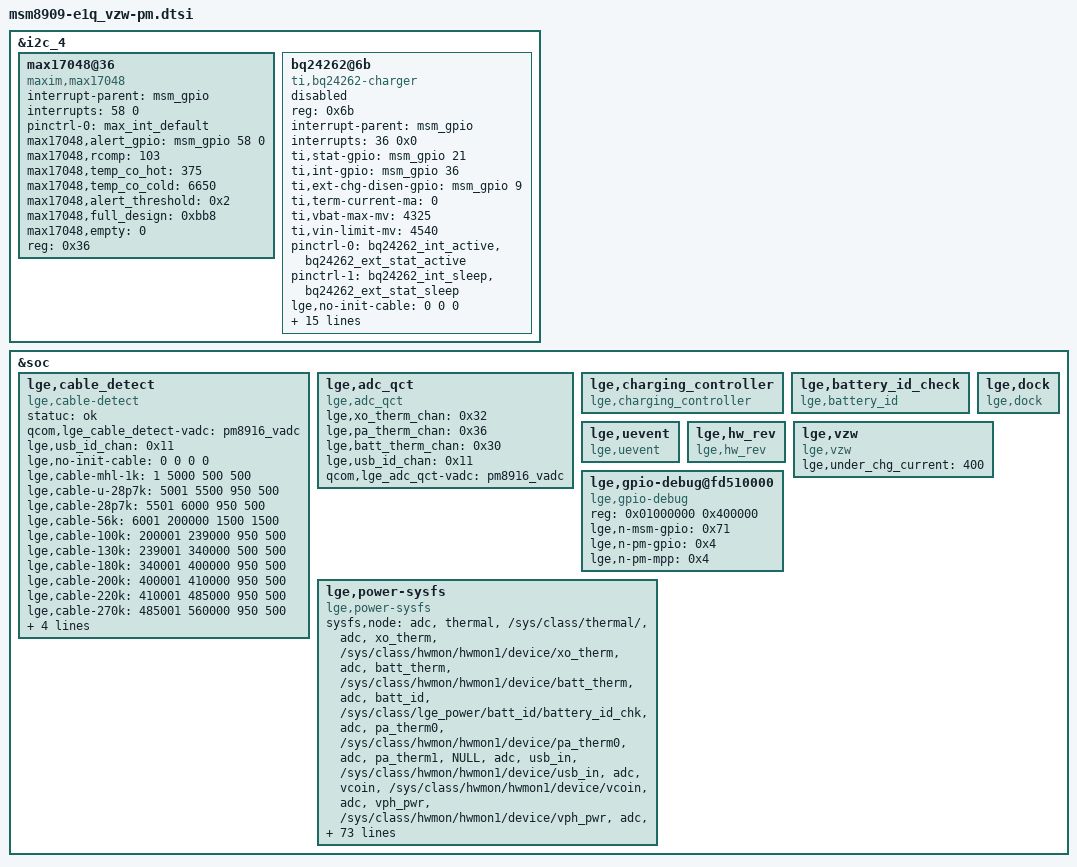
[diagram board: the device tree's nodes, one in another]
/* Copyright (c) 2014, The Linux Foundation. All rights reserved.
 *
 * This program is free software; you can redistribute it and/or modify
 * it under the terms of the GNU General Public License version 2 and
 * only version 2 as published by the Free Software Foundation.
 *
 * This program is distributed in the hope that it will be useful,
 * but WITHOUT ANY WARRANTY; without even the implied warranty of
 * MERCHANTABILITY or FITNESS FOR A PARTICULAR PURPOSE.  See the
 * GNU General Public License for more details.
 */

&i2c_4 {
	/* BLSP1 QUP4 */
	max17048@36 {
		compatible = "maxim,max17048";
		interrupt-parent = <&msm_gpio>;
		interrupts = <58 0>;
		pinctrl-names = "default";
		pinctrl-0 = <&max_int_default>;
		max17048,alert_gpio = <&msm_gpio 58 0>;
		max17048,rcomp = <103>;
		max17048,temp_co_hot = <375>;
		max17048,temp_co_cold = <6650>;
		max17048,alert_threshold = <0x2>;
		max17048,full_design = <0xbb8>;
		max17048,empty = <0>;
		reg = <0x36>;
	};

	bq24262@6b {
		status = "disabled";
		compatible = "ti,bq24262-charger";
		reg = <0x6b>;
		interrupt-parent = <&msm_gpio>;
		interrupts = <36 0x0>;
		ti,stat-gpio = <&msm_gpio 21 0>;
		ti,int-gpio = <&msm_gpio 36 0>;
		ti,ext-chg-disen-gpio = <&msm_gpio 9 0>;
		ti,term-current-ma = <0>;
		ti,vbat-max-mv = <4325>;	/* Step unit 20 mV, battery available voltage(x = 4.375) : x-0.025 ~ x ~ x+0.025 */
		ti,vin-limit-mv = <4540>;
		/* Pins config setting */
		pinctrl-names = "default", "sleep";
		pinctrl-0 = <&bq24262_int_active &bq24262_ext_stat_active>;
		pinctrl-1 = <&bq24262_int_sleep &bq24262_ext_stat_sleep>;

		/* Each model is defferently value */
		lge,no-init-cable = <0 0 0>;
		lge,cable-mhl-1k = <5000 500 500>;
		lge,cable-u-28p7k = <5500 1200 500>;
		lge,cable-28p7k = <6000 1200 500>;
		lge,cable-56k = <200000 1500 1500>;
		lge,cable-100k = <239000 1200 500>;
		lge,cable-130k = <340000 1500 1500>;
		lge,cable-180k = <400000 1200 500>;
		lge,cable-200k = <410000 1200 500>;
		lge,cable-220k = <485000 1200 500>;
		lge,cable-270k = <560000 1200 500>;
		lge,cable-330k = <735000 1200 500>;
		lge,cable-620k = <955000 1200 500>;
		lge,cable-910k = <1140000 1500 1500>;
		lge,cable-none = <1900000 1200  500>;

		qcom,bq24262-vadc = <&pm8909_vadc>;
	};
};

&soc {

	lge,cable_detect {
		statuc = "ok";
		compatible = "lge,cable-detect";
		qcom,lge_cable_detect-vadc = <&pm8916_vadc>;

		lge,usb_id_chan = <0x11>;

		lge,no-init-cable = <0 0 0 0>;
		lge,cable-mhl-1k = <1 5000 500 500>;
		lge,cable-u-28p7k = <5001 5500 950 500>;
		lge,cable-28p7k = <5501 6000 950 500>;
		lge,cable-56k = <6001 200000 1500 1500>;
		lge,cable-100k = <200001 239000 950 500>;
		lge,cable-130k = <239001 340000 500 500>;
		lge,cable-180k = <340001 400000 950 500>;
		lge,cable-200k = <400001 410000 950 500>;
		lge,cable-220k = <410001 485000 950 500>;
		lge,cable-270k = <485001 560000 950 500>;
		lge,cable-330k = <560001 735000 950 500>;
		lge,cable-620k = <735001 955000 950 500>;
		lge,cable-910k = <955001 1140000 1500 1500>;
		lge,cable-none = <1140001 1900000 950 500>;
	};

	lge,adc_qct {
		compatible = "lge,adc_qct";
		lge,xo_therm_chan = <0x32>;
		lge,pa_therm_chan = <0x36>;
		lge,batt_therm_chan = <0x30>;
		lge,usb_id_chan = <0x11>;
		qcom,lge_adc_qct-vadc = <&pm8916_vadc>;
	};

	lge,charging_controller {
		compatible = "lge,charging_controller";
	};

	lge,battery_id_check {
		compatible = "lge,battery_id";
	};

	lge,dock {
		compatible = "lge,dock";
	};

	lge,uevent {
		compatible = "lge,uevent";
	};

	lge,hw_rev {
		compatible = "lge,hw_rev";
	};

	lge,vzw {
		compatible = "lge,vzw";
		lge,under_chg_current = <400>;
	};

	lge,gpio-debug@fd510000 {
		compatible = "lge,gpio-debug";
		reg = <0x01000000 0x400000>;
		reg-names = "tlmm-base";
		lge,n-msm-gpio = <0x71>;
		lge,n-pm-gpio = <0x4>;
		lge,n-pm-mpp = <0x4>;
	};
};

&soc {
	lge,power-sysfs {
		compatible = "lge,power-sysfs";

		sysfs,node =
			/* group , user_node,  kernel node */
			/* ADC/MPP */
			"adc", "thermal", "/sys/class/thermal/",
			"adc", "xo_therm", "/sys/class/hwmon/hwmon1/device/xo_therm",
			"adc", "batt_therm", "/sys/class/hwmon/hwmon1/device/batt_therm",
			"adc", "batt_id", "/sys/class/lge_power/batt_id/battery_id_chk",
			"adc", "pa_therm0", "/sys/class/hwmon/hwmon1/device/pa_therm0",
			"adc", "pa_therm1", "NULL",
			"adc", "usb_in", "/sys/class/hwmon/hwmon1/device/usb_in",
			"adc", "vcoin", "/sys/class/hwmon/hwmon1/device/vcoin",
			"adc", "vph_pwr", "/sys/class/hwmon/hwmon1/device/vph_pwr",
			"adc", "usb_id", "/sys/class/hwmon/hwmon1/device/usb_id",
			/* Battery */
			"battery", "capacity", "/sys/class/power_supply/battery/capacity",
			"battery", "health", "/sys/class/power_supply/battery/health",
			"battery", "present", "/sys/class/power_supply/battery/present",
			"battery", "pseudo_batt", "/sys/class/power_supply/battery/pseudo_batt",
			"battery", "status", "/sys/class/power_supply/battery/status",
			"battery", "temp", "/sys/class/power_supply/battery/temp",
			"battery", "valid_batt_id", "/sys/class/lge_power/batt_id/valid_batt_id",
			"battery", "voltage_now", "/sys/class/power_supply/battery/voltage_now",
			"battery", "check_batt_id_for_aat", "/sys/class/lge_power/batt_id/batt_id_for_aat",
			"battery", "vzw_chg", "/sys/class/lge_power/vzw/vzw_chg",
			/* Charger */
			"charger", "ac_online", "NULL",
			"charger", "usb_online", "/sys/class/power_supply/usb/online",
			"charger", "present", "/sys/class/power_supply/usb/present",
			"charger", "wlc_online", "NULL",
			"charger", "type", "/sys/class/power_supply/usb/type",
			"charger", "time_out", "/sys/class/power_supply/battery/safety_timer",
			"charger", "charging_enabled", "/sys/class/power_supply/battery/charging_enabled",
			"charger", "ibat_current", "/sys/class/power_supply/battery/current_now",
			"charger", "ichg_current", "/sys/class/power_supply/usb/current_max",
			"charger", "iusb_control", "NULL",
			"charger", "thermal_mitigation", "/sys/module/lge_power_class_charging_controller/parameters/lgcc_thermal_mitigation",
			"charger", "wlc_thermal_mitigation", "NULL",
			"charger", "usb_parallel_chg_status", "NULL",
			"charger", "usb_parallel_charging_enabled", "NULL",
			/* LCD Backlight */
			"lcd", "brightness", "/sys/class/leds/lcd-backlight/brightness",
			"lcd", "max_brightness", "/sys/class/leds/lcd-backlight/max_brightness",
			/* KEY LED */
			"key_led", "red_brightness", "/sys/class/leds/R/brightness",
			"key_led", "green_brightness", "/sys/class/leds/G/brightness",
			"key_led", "blue_brightness", "/sys/class/leds/B/brightness",
			/* CPU */
			"cpu", "cpu_idle_modes", "NULL",
			/* GPU */
			"gpu", "busy", "/sys/class/kgsl/kgsl-3d0/gpubusy",
			/* PLATFORM */
			"platform", "speed_bin", "NULL",
			"platform", "pvs_bin", "NULL",
			"platform", "power_state", "/sys/power/autosleep",
			"platform", "poweron_alarm", "/sys/module/qpnp_rtc/parameters/poweron_alarm",
			"platform", "pcb_rev", "/sys/class/hwmon/hwmon1/device/pcb_rev",
			/* testmode */
			"testmode", "charge", "/sys/class/power_supply/battery/device/at_charge",
			"testmode", "chcomp", "/sys/class/power_supply/battery/device/at_chcomp",
			"testmode", "chgmodeoff", "/sys/class/power_supply/battery/charging_enabled",
			"testmode", "fuelrst", "/sys/bus/i2c/drivers/rt5058/4-0034/rt5058-fuelgauge/at_fuelrst",
			"testmode", "rtc_time", "/dev/rtc0",
			"testmode", "pmrst", "NULL",
			"testmode", "battexit", "/sys/class/power_supply/battery/present",
			"testmode", "hw_rev", "/sys/class/lge_power/hw_rev/hw_rev"
			;
	};
};
